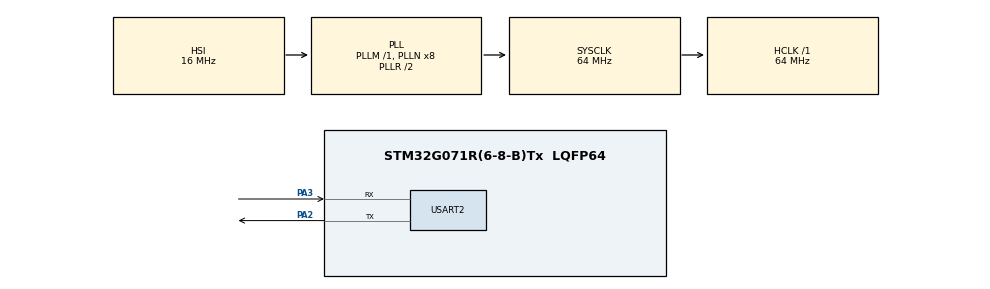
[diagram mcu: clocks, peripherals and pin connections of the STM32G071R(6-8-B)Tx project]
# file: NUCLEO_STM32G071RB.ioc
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Mcu.Family=STM32G0
Mcu.Name=STM32G071R(6-8-B)Tx
Mcu.Package=LQFP64
PA13.GPIO_Label=TMS
PA13.Mode=Serial_Wire
PA13.Signal=SYS_SWDIO
PA14-BOOT0.GPIO_Label=TCK
PA14-BOOT0.Mode=Serial_Wire
PA14-BOOT0.Signal=SYS_SWCLK
PA2.Mode=Asynchronous
PA2.Signal=USART2_TX
PA3.Mode=Asynchronous
PA3.Signal=USART2_RX
PC13.Mode=SYS_WakeUp1
PC13.Signal=SYS_WKUP2
PC14-OSC32_IN\ (PC14).Mode=LSE-External-Oscillator
PC14-OSC32_IN\ (PC14).Signal=RCC_OSC32_IN
PC15-OSC32_OUT\ (PC15).Mode=LSE-External-Oscillator
PC15-OSC32_OUT\ (PC15).Signal=RCC_OSC32_OUT
PF0-OSC_IN\ (PF0).GPIO_Label=MCO
PF0-OSC_IN\ (PF0).Mode=HSE-External-Clock-Source
PF0-OSC_IN\ (PF0).Signal=RCC_OSC_IN
ProjectManager.HeapSize=0x200
ProjectManager.StackSize=0x400
ProjectManager.TargetToolchain=MDK-ARM V5.27
RCC.ADCFreq_Value=64000000
RCC.AHBFreq_Value=64000000
RCC.CortexFreq_Value=64000000
RCC.EXTERNAL_CLOCK_VALUE=48000
RCC.HCLKFreq_Value=64000000
RCC.HSE_VALUE=8000000
RCC.HSI_VALUE=16000000
RCC.SYSCLKFreq_VALUE=64000000
RCC.SYSCLKSource=RCC_SYSCLKSOURCE_PLLCLK
RCC.VCOOutputFreq_Value=128000000
USART2.VirtualMode-Asynchronous=VM_ASYNC
VP_SYS_VS_DBSignals.Mode=DisableDeadBatterySignals
board=custom

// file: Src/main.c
/**
  ******************************************************************************
  * @file           : main.c
  * @brief          : Main program body
  ******************************************************************************
  * @attention
  *
  * <h2><center>&copy; Copyright (c) 2019 STMicroelectronics.
  * All rights reserved.</center></h2>
  *
  * This software component is licensed by ST under BSD 3-Clause license,
  * the "License"; You may not use this file except in compliance with the
  * License. You may obtain a copy of the License at:
  *                        opensource.org/licenses/BSD-3-Clause
  *
  ******************************************************************************
  */
/* USER CODE END Header */

#include "cmsis_os.h"
#include "main.h"

UART_HandleTypeDef huart2;

void SystemClock_Config(void);
static void MX_GPIO_Init(void);
static void MX_USART2_UART_Init(void);

/* USER CODE BEGIN 0 */

#define APPLICATION_TASK_STK_SIZE       1024
extern void application_entry(void *arg);
osThreadDef(application_entry, osPriorityNormal, 1, APPLICATION_TASK_STK_SIZE);

__weak void application_entry(void *arg)
{
    while (1) {
        printf("This is a demo task,please use your task entry!\r\n");
        tos_task_delay(1000);
    }
}
int fputc(int ch, FILE *f)
{
  if (ch == '\n') {
    HAL_UART_Transmit(&huart2, (void *)"\r", 1,30000);
  }
  HAL_UART_Transmit(&huart2, (uint8_t *)&ch, 1, 0xFFFF);
  return ch;
}

int _write(int fd, char *ptr, int len)
{
    (void)HAL_UART_Transmit(&huart2, (uint8_t *)ptr, len, 0xFFFF);
    return len;
}

int fgetc(FILE *f)
{
  /* Place your implementation of fgetc here */
  /* e.g. readwrite a character to the USART2 and Loop until the end of transmission */
  uint8_t ch = 0;
  //uint32_t recv_size;
  HAL_UART_Receive(&huart2, &ch, 1,30000);
  return ch;
}

void board_init(void)
{
  HAL_Init();
  SystemClock_Config();
  MX_GPIO_Init();
  MX_USART2_UART_Init();
}
/* USER CODE END 0 */

int main(void)
{

    board_init();
    printf("Welcome to TencentOS tiny\r\n");
    osKernelInitialize();
    osThreadCreate(osThread(application_entry), NULL);
    osKernelStart();
}

void SystemClock_Config(void)
{
  RCC_OscInitTypeDef RCC_OscInitStruct = {0};
  RCC_ClkInitTypeDef RCC_ClkInitStruct = {0};
  RCC_PeriphCLKInitTypeDef PeriphClkInit = {0};

  /** Configure the main internal regulator output voltage
  */
  HAL_PWREx_ControlVoltageScaling(PWR_REGULATOR_VOLTAGE_SCALE1);
  /** Initializes the CPU, AHB and APB busses clocks
  */
  RCC_OscInitStruct.OscillatorType = RCC_OSCILLATORTYPE_HSI;
  RCC_OscInitStruct.HSIState = RCC_HSI_ON;
  RCC_OscInitStruct.HSIDiv = RCC_HSI_DIV1;
  RCC_OscInitStruct.HSICalibrationValue = RCC_HSICALIBRATION_DEFAULT;
  RCC_OscInitStruct.PLL.PLLState = RCC_PLL_ON;
  RCC_OscInitStruct.PLL.PLLSource = RCC_PLLSOURCE_HSI;
  RCC_OscInitStruct.PLL.PLLM = RCC_PLLM_DIV1;
  RCC_OscInitStruct.PLL.PLLN = 8;
  RCC_OscInitStruct.PLL.PLLP = RCC_PLLP_DIV2;
  RCC_OscInitStruct.PLL.PLLQ = RCC_PLLQ_DIV2;
  RCC_OscInitStruct.PLL.PLLR = RCC_PLLR_DIV2;
  if (HAL_RCC_OscConfig(&RCC_OscInitStruct) != HAL_OK)
  {
    Error_Handler();
  }
  /** Initializes the CPU, AHB and APB busses clocks
  */
  RCC_ClkInitStruct.ClockType = RCC_CLOCKTYPE_HCLK|RCC_CLOCKTYPE_SYSCLK
                              |RCC_CLOCKTYPE_PCLK1;
  RCC_ClkInitStruct.SYSCLKSource = RCC_SYSCLKSOURCE_PLLCLK;
  RCC_ClkInitStruct.AHBCLKDivider = RCC_SYSCLK_DIV1;
  RCC_ClkInitStruct.APB1CLKDivider = RCC_HCLK_DIV1;

  if (HAL_RCC_ClockConfig(&RCC_ClkInitStruct, FLASH_LATENCY_2) != HAL_OK)
  {
    Error_Handler();
  }
  /** Initializes the peripherals clocks
  */
  PeriphClkInit.PeriphClockSelection = RCC_PERIPHCLK_USART2;
  PeriphClkInit.Usart2ClockSelection = RCC_USART2CLKSOURCE_PCLK1;
  if (HAL_RCCEx_PeriphCLKConfig(&PeriphClkInit) != HAL_OK)
  {
    Error_Handler();
  }
}

static void MX_USART2_UART_Init(void)
{

  huart2.Instance = USART2;
  huart2.Init.BaudRate = 115200;
  huart2.Init.WordLength = UART_WORDLENGTH_8B;
  huart2.Init.StopBits = UART_STOPBITS_1;
  huart2.Init.Parity = UART_PARITY_NONE;
  huart2.Init.Mode = UART_MODE_TX_RX;
  huart2.Init.HwFlowCtl = UART_HWCONTROL_NONE;
  huart2.Init.OverSampling = UART_OVERSAMPLING_16;
  huart2.Init.OneBitSampling = UART_ONE_BIT_SAMPLE_DISABLE;
  huart2.Init.ClockPrescaler = UART_PRESCALER_DIV1;
  huart2.AdvancedInit.AdvFeatureInit = UART_ADVFEATURE_NO_INIT;
  if (HAL_UART_Init(&huart2) != HAL_OK)
  {
    Error_Handler();
  }
  if (HAL_UARTEx_SetTxFifoThreshold(&huart2, UART_TXFIFO_THRESHOLD_1_8) != HAL_OK)
  {
    Error_Handler();
  }
  if (HAL_UARTEx_SetRxFifoThreshold(&huart2, UART_RXFIFO_THRESHOLD_1_8) != HAL_OK)
  {
    Error_Handler();
  }
  if (HAL_UARTEx_DisableFifoMode(&huart2) != HAL_OK)
  {
    Error_Handler();
  }

}

static void MX_GPIO_Init(void)
{

  /* GPIO Ports Clock Enable */
  __HAL_RCC_GPIOC_CLK_ENABLE();
  __HAL_RCC_GPIOF_CLK_ENABLE();
  __HAL_RCC_GPIOA_CLK_ENABLE();

}

void Error_Handler(void)
{
}

/************************ (C) COPYRIGHT STMicroelectronics *****END OF FILE****/
